# apollo510 register map
Vendor: Ambiq Micro; Series: Apollo; File version: 1.0
CPU: CM55 r1p1, little endian, MPU, FPU, double-precision FPU, DSP, I-cache, D-cache, VTOR, ITCM, DTCM, 4 interrupt priority bits, 0 interrupts, 8 SAU regions
Registers are 32-bit, read-write, reset 0x0 unless marked. A register's access mark holds for its fields unless they carry their own. Offsets are from the block's base; [hi:lo] are bit positions; {n}, {i} and the like mark numbered series; 'fields as' and 'values as' point back to an identical list.

## GPIO (part 4 of 7) — General Purpose IO
Base 0x40010000
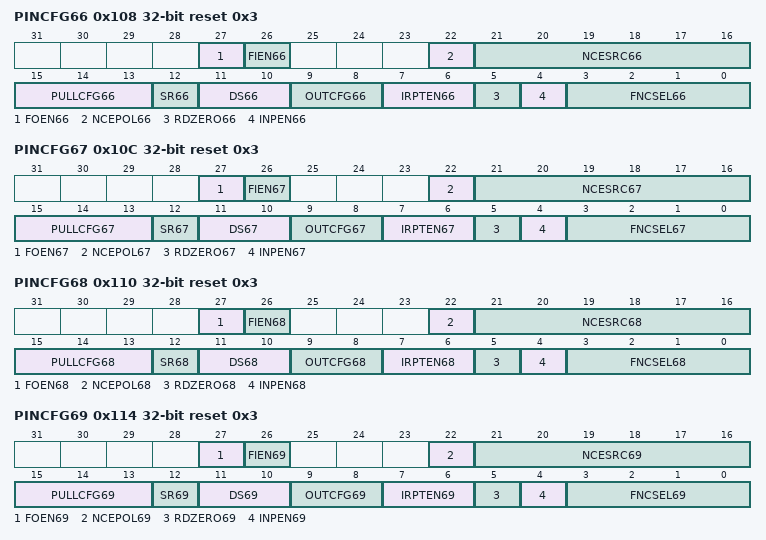
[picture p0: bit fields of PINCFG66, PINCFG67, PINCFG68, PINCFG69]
0x108 PINCFG66 reset 0x3 — Controls the operation of GPIO pin 66.
  [27] FOEN66 — Force output enable active regardless of function selected. Otherwise the selected function will enable the output only when needed
  [26] FIEN66 — Force input enable active regardless of function selected. Otherwise the selected function will enable the input only when needed
  [22] NCEPOL66 — Polarity select for NCE for GPIO 66
    0=LOW (Polarity is active low); 1=HIGH (Polarity is active high)
  [21:16] NCESRC66 — IOMSTR/MSPI N Chip Select 66, DISP control signals DE, CSX, and CS. Polarity is determined by CE_POLARITY field
    {v}=IOM0CE{v} (IOM 0 NCE {v} module) (v=0..3); {v}=IOM1CE{v-4} (IOM 1 NCE {v-4} module) (v=4..7); {v}=IOM2CE{v-8} (IOM 2 NCE {v-8} module) (v=8..11); {v}=IOM3CE{v-12} (IOM 3 NCE {v-12} module) (v=12..15); {v}=IOM4CE{v-16} (IOM 4 NCE {v-16} module) (v=16..19); {v}=IOM5CE{v-20} (IOM 5 NCE {v-20} module) (v=20..23); {v}=IOM6CE{v-24} (IOM 6 NCE {v-24} module) (v=24..27); {v}=IOM7CE{v-28} (IOM 7 NCE {v-28} module) (v=28..31); 48=DC_DPI_DE (DC DPI DE module); 49=DISP_CONT_CSX (DISP CONT CSX module); 50=DC_SPI_CS_N (DC SPI CS_N module); 51=DC_QSPI_CS_N (DC QSPI CS_N module); 52=DC_RESX (DC module RESX)
  [15:13] PULLCFG66 — Pullup/Pulldown configuration for GPIO 66
    0=DIS (No pullup or pulldown selected); 1=PD50K (50K Pulldown selected); 2=PU50K (50K Pullup selected)
  [12] SR66 — Configure high or low drive strength
    0=LDRV (Select the lower of the two drive strength selections); 1=HDRV (Select the higher of the two drive strength selections)
  [11:10] DS66 — Drive strength selection for High Speed GPIO 66
    0=0P12X_0P63X (0.12x output driver selected if SR66 = 0, 0.63x output driver selected if SR66 = 1); 1=0P25X_0P75X (0.25x output driver selected if SR66 = 0, 0.75x output driver selected if SR66 = 1); 2=0P37X_0P88X (0.37x output driver selected if SR66 = 0, 0.88x output driver selected if SR66 = 1); 3=0P5X_1P0X (0.5x output driver selected if SR66 = 0, 1.0x output driver selected if SR66 = 1)
  [9:8] OUTCFG66 — Pin IO mode selection for GPIO pin 66
    0=DIS (Output Disabled); 1=PUSHPULL (Output configured in push pull mode. Will drive 0 and 1 values on pin.); 2=OD (Output configured in open drain mode. Will only drive pin low, tristate otherwise.); 3=TS (Output configured in Tristate-able push pull mode. Will drive 0, 1 of HiZ on pin.)
  [7:6] IRPTEN66 — Interrupt enable for GPIO 66
    0=DIS (Interrupts are disabled for this GPIO); 1=INTFALL (Interrupts are enabled for falling edge transition on this GPIO); 2=INTRISE (Interrupts are enabled for rising edge transitions on this GPIO); 3=INTANY (Interrupts are enabled for any edge transition on this GPIO)
  [5] RDZERO66 — Return 0 for read data on GPIO 66
  [4] INPEN66 — Input enable for GPIO 66
  [3:0] FNCSEL66 — Function select for GPIO pin 66
    0=MSPI0_2 (MSPI Master 0 Interface Signal); 1=CLKOUT (Oscillator output clock); 2=SWO (Serial Wire Output); 3=GPIO (General purpose I/O); 4=UART0TX (UART transmit output (UART 0)); 5=UART1TX (UART transmit output (UART 1)); 6=CT66 (Timer/Counter input or output; Selection of direction is done via CTIMER register settings.); 7=NCE66 (IOMSTR N Chip Select. Polarity is determined by CE_POLARITY field); 8=OBSBUS2 (Observation bus bit 2); 11=FPIO (Fast PIO)
0x10C PINCFG67 reset 0x3 — Controls the operation of GPIO pin 67.
  [27] FOEN67 — Force output enable active regardless of function selected. Otherwise the selected function will enable the output only when needed
  [26] FIEN67 — Force input enable active regardless of function selected. Otherwise the selected function will enable the input only when needed
  [22] NCEPOL67 — Polarity select for NCE for GPIO 67
    values as PINCFG66.NCEPOL66
  [21:16] NCESRC67 — IOMSTR/MSPI N Chip Select 67, DISP control signals DE, CSX, and CS. Polarity is determined by CE_POLARITY field
    values as PINCFG66.NCESRC66
  [15:13] PULLCFG67 — Pullup/Pulldown configuration for GPIO 67
    values as PINCFG66.PULLCFG66
  [12] SR67 — Configure high or low drive strength
    values as PINCFG66.SR66
  [11:10] DS67 — Drive strength selection for High Speed GPIO 67
    0=0P12X_0P63X (0.12x output driver selected if SR67 = 0, 0.63x output driver selected if SR67 = 1); 1=0P25X_0P75X (0.25x output driver selected if SR67 = 0, 0.75x output driver selected if SR67 = 1); 2=0P37X_0P88X (0.37x output driver selected if SR67 = 0, 0.88x output driver selected if SR67 = 1); 3=0P5X_1P0X (0.5x output driver selected if SR67 = 0, 1.0x output driver selected if SR67 = 1)
  [9:8] OUTCFG67 — Pin IO mode selection for GPIO pin 67
    values as PINCFG66.OUTCFG66
  [7:6] IRPTEN67 — Interrupt enable for GPIO 67
    values as PINCFG66.IRPTEN66
  [5] RDZERO67 — Return 0 for read data on GPIO 67
  [4] INPEN67 — Input enable for GPIO 67
  [3:0] FNCSEL67 — Function select for GPIO pin 67
    0=MSPI0_3 (MSPI Master 0 Interface Signal); 1=CLKOUT (Oscillator output clock); 2=SWO (Serial Wire Output); 3=GPIO (General purpose I/O); 4=UART2TX (UART transmit output (UART 2)); 5=UART3TX (UART transmit output (UART 3)); 6=CT67 (Timer/Counter input or output; Selection of direction is done via CTIMER register settings.); 7=NCE67 (IOMSTR N Chip Select. Polarity is determined by CE_POLARITY field); 8=OBSBUS3 (Observation bus bit 3); 11=FPIO (Fast PIO)
0x110 PINCFG68 reset 0x3 — Controls the operation of GPIO pin 68.
  [27] FOEN68 — Force output enable active regardless of function selected. Otherwise the selected function will enable the output only when needed
  [26] FIEN68 — Force input enable active regardless of function selected. Otherwise the selected function will enable the input only when needed
  [22] NCEPOL68 — Polarity select for NCE for GPIO 68
    values as PINCFG66.NCEPOL66
  [21:16] NCESRC68 — IOMSTR/MSPI N Chip Select 68, DISP control signals DE, CSX, and CS. Polarity is determined by CE_POLARITY field
    values as PINCFG66.NCESRC66
  [15:13] PULLCFG68 — Pullup/Pulldown configuration for GPIO 68
    values as PINCFG66.PULLCFG66
  [12] SR68 — Configure high or low drive strength
    values as PINCFG66.SR66
  [11:10] DS68 — Drive strength selection for High Speed GPIO 68
    0=0P12X_0P63X (0.12x output driver selected if SR68 = 0, 0.63x output driver selected if SR68 = 1); 1=0P25X_0P75X (0.25x output driver selected if SR68 = 0, 0.75x output driver selected if SR68 = 1); 2=0P37X_0P88X (0.37x output driver selected if SR68 = 0, 0.88x output driver selected if SR68 = 1); 3=0P5X_1P0X (0.5x output driver selected if SR68 = 0, 1.0x output driver selected if SR68 = 1)
  [9:8] OUTCFG68 — Pin IO mode selection for GPIO pin 68
    values as PINCFG66.OUTCFG66
  [7:6] IRPTEN68 — Interrupt enable for GPIO 68
    values as PINCFG66.IRPTEN66
  [5] RDZERO68 — Return 0 for read data on GPIO 68
  [4] INPEN68 — Input enable for GPIO 68
  [3:0] FNCSEL68 — Function select for GPIO pin 68
    0=MSPI0_4 (MSPI Master 0 Interface Signal); 1=SWO (Serial Wire Output); 3=GPIO (General purpose I/O); 4=UART0RX (UART receive input (UART 0)); 5=UART1RX (UART receive input (UART 1)); 6=CT68 (Timer/Counter input or output; Selection of direction is done via CTIMER register settings.); 7=NCE68 (IOMSTR N Chip Select. Polarity is determined by CE_POLARITY field); 8=OBSBUS4 (Observation bus bit 4); 11=FPIO (Fast PIO)
0x114 PINCFG69 reset 0x3 — Controls the operation of GPIO pin 69.
  [27] FOEN69 — Force output enable active regardless of function selected. Otherwise the selected function will enable the output only when needed
  [26] FIEN69 — Force input enable active regardless of function selected. Otherwise the selected function will enable the input only when needed
  [22] NCEPOL69 — Polarity select for NCE for GPIO 69
    values as PINCFG66.NCEPOL66
  [21:16] NCESRC69 — IOMSTR/MSPI N Chip Select 69, DISP control signals DE, CSX, and CS. Polarity is determined by CE_POLARITY field
    values as PINCFG66.NCESRC66
  [15:13] PULLCFG69 — Pullup/Pulldown configuration for GPIO 69
    values as PINCFG66.PULLCFG66
  [12] SR69 — Configure high or low drive strength
    values as PINCFG66.SR66
  [11:10] DS69 — Drive strength selection for High Speed GPIO 69
    0=0P12X_0P63X (0.12x output driver selected if SR69 = 0, 0.63x output driver selected if SR69 = 1); 1=0P25X_0P75X (0.25x output driver selected if SR69 = 0, 0.75x output driver selected if SR69 = 1); 2=0P37X_0P88X (0.37x output driver selected if SR69 = 0, 0.88x output driver selected if SR69 = 1); 3=0P5X_1P0X (0.5x output driver selected if SR69 = 0, 1.0x output driver selected if SR69 = 1)
  [9:8] OUTCFG69 — Pin IO mode selection for GPIO pin 69
    values as PINCFG66.OUTCFG66
  [7:6] IRPTEN69 — Interrupt enable for GPIO 69
    values as PINCFG66.IRPTEN66
  [5] RDZERO69 — Return 0 for read data on GPIO 69
  [4] INPEN69 — Input enable for GPIO 69
  [3:0] FNCSEL69 — Function select for GPIO pin 69
    0=MSPI0_5 (MSPI Master 0 Interface Signal); 1=32KHzXT (32kHZ from analog); 2=SWO (Serial Wire Output); 3=GPIO (General purpose I/O); 4=UART2RX (UART receive input (UART 2)); 5=UART3RX (UART receive input (UART 3)); 6=CT69 (Timer/Counter input or output; Selection of direction is done via CTIMER register settings.); 7=NCE69 (IOMSTR N Chip Select. Polarity is determined by CE_POLARITY field); 8=OBSBUS5 (Observation bus bit 5); 11=FPIO (Fast PIO)
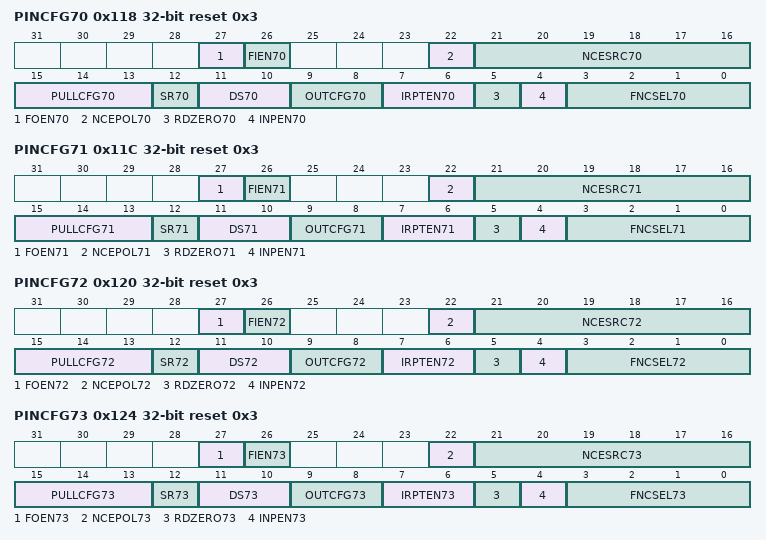
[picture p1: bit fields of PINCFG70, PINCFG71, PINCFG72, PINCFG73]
0x118 PINCFG70 reset 0x3 — Controls the operation of GPIO pin 70.
  [27] FOEN70 — Force output enable active regardless of function selected. Otherwise the selected function will enable the output only when needed
  [26] FIEN70 — Force input enable active regardless of function selected. Otherwise the selected function will enable the input only when needed
  [22] NCEPOL70 — Polarity select for NCE for GPIO 70
    values as PINCFG66.NCEPOL66
  [21:16] NCESRC70 — IOMSTR/MSPI N Chip Select 70, DISP control signals DE, CSX, and CS. Polarity is determined by CE_POLARITY field
    values as PINCFG66.NCESRC66
  [15:13] PULLCFG70 — Pullup/Pulldown configuration for GPIO 70
    values as PINCFG66.PULLCFG66
  [12] SR70 — Configure high or low drive strength
    values as PINCFG66.SR66
  [11:10] DS70 — Drive strength selection for High Speed GPIO 70
    0=0P12X_0P63X (0.12x output driver selected if SR70 = 0, 0.63x output driver selected if SR70 = 1); 1=0P25X_0P75X (0.25x output driver selected if SR70 = 0, 0.75x output driver selected if SR70 = 1); 2=0P37X_0P88X (0.37x output driver selected if SR70 = 0, 0.88x output driver selected if SR70 = 1); 3=0P5X_1P0X (0.5x output driver selected if SR70 = 0, 1.0x output driver selected if SR70 = 1)
  [9:8] OUTCFG70 — Pin IO mode selection for GPIO pin 70
    values as PINCFG66.OUTCFG66
  [7:6] IRPTEN70 — Interrupt enable for GPIO 70
    values as PINCFG66.IRPTEN66
  [5] RDZERO70 — Return 0 for read data on GPIO 70
  [4] INPEN70 — Input enable for GPIO 70
  [3:0] FNCSEL70 — Function select for GPIO pin 70
    0=MSPI0_6 (MSPI Master 0 Interface Signal); 1=32KHzXT (32kHZ from analog); 2=SWTRACE0 (Serial Wire Debug Trace Output 0); 3=GPIO (General purpose I/O); 4=UART0RTS (UART Request to Send (RTS) (UART 0)); 5=UART1RTS (UART Request to Send (RTS) (UART 1)); 6=CT70 (Timer/Counter input or output; Selection of direction is done via CTIMER register settings.); 7=NCE70 (IOMSTR N Chip Select. Polarity is determined by CE_POLARITY field); 8=OBSBUS6 (Observation bus bit 6); 11=FPIO (Fast PIO)
0x11C PINCFG71 reset 0x3 — Controls the operation of GPIO pin 71.
  [27] FOEN71 — Force output enable active regardless of function selected. Otherwise the selected function will enable the output only when needed
  [26] FIEN71 — Force input enable active regardless of function selected. Otherwise the selected function will enable the input only when needed
  [22] NCEPOL71 — Polarity select for NCE for GPIO 71
    values as PINCFG66.NCEPOL66
  [21:16] NCESRC71 — IOMSTR/MSPI N Chip Select 71, DISP control signals DE, CSX, and CS. Polarity is determined by CE_POLARITY field
    values as PINCFG66.NCESRC66
  [15:13] PULLCFG71 — Pullup/Pulldown configuration for GPIO 71
    values as PINCFG66.PULLCFG66
  [12] SR71 — Configure high or low drive strength
    values as PINCFG66.SR66
  [11:10] DS71 — Drive strength selection for High Speed GPIO 71
    0=0P12X_0P63X (0.12x output driver selected if SR71 = 0, 0.63x output driver selected if SR71 = 1); 1=0P25X_0P75X (0.25x output driver selected if SR71 = 0, 0.75x output driver selected if SR71 = 1); 2=0P37X_0P88X (0.37x output driver selected if SR71 = 0, 0.88x output driver selected if SR71 = 1); 3=0P5X_1P0X (0.5x output driver selected if SR71 = 0, 1.0x output driver selected if SR71 = 1)
  [9:8] OUTCFG71 — Pin IO mode selection for GPIO pin 71
    values as PINCFG66.OUTCFG66
  [7:6] IRPTEN71 — Interrupt enable for GPIO 71
    values as PINCFG66.IRPTEN66
  [5] RDZERO71 — Return 0 for read data on GPIO 71
  [4] INPEN71 — Input enable for GPIO 71
  [3:0] FNCSEL71 — Function select for GPIO pin 71
    0=MSPI0_7 (MSPI Master 0 Interface Signal); 1=CLKOUT (Oscillator output clock); 2=SWTRACE1 (Serial Wire Debug Trace Output 1); 3=GPIO (General purpose I/O); 4=UART0CTS (UART Clear to Send (CTS) (UART 0)); 5=UART3RTS (UART Request to Send (RTS) (UART 3)); 6=CT71 (Timer/Counter input or output; Selection of direction is done via CTIMER register settings.); 7=NCE71 (IOMSTR N Chip Select. Polarity is determined by CE_POLARITY field); 8=OBSBUS7 (Observation bus bit 7); 11=FPIO (Fast PIO)
0x120 PINCFG72 reset 0x3 — Controls the operation of GPIO pin 72.
  [27] FOEN72 — Force output enable active regardless of function selected. Otherwise the selected function will enable the output only when needed
  [26] FIEN72 — Force input enable active regardless of function selected. Otherwise the selected function will enable the input only when needed
  [22] NCEPOL72 — Polarity select for NCE for GPIO 72
    values as PINCFG66.NCEPOL66
  [21:16] NCESRC72 — IOMSTR/MSPI N Chip Select 72, DISP control signals DE, CSX, and CS. Polarity is determined by CE_POLARITY field
    values as PINCFG66.NCESRC66
  [15:13] PULLCFG72 — Pullup/Pulldown configuration for GPIO 72
    values as PINCFG66.PULLCFG66
  [12] SR72 — Configure high or low drive strength
    values as PINCFG66.SR66
  [11:10] DS72 — Drive strength selection for High Speed GPIO 72
    0=0P12X_0P63X (0.12x output driver selected if SR72 = 0, 0.63x output driver selected if SR72 = 1); 1=0P25X_0P75X (0.25x output driver selected if SR72 = 0, 0.75x output driver selected if SR72 = 1); 2=0P37X_0P88X (0.37x output driver selected if SR72 = 0, 0.88x output driver selected if SR72 = 1); 3=0P5X_1P0X (0.5x output driver selected if SR72 = 0, 1.0x output driver selected if SR72 = 1)
  [9:8] OUTCFG72 — Pin IO mode selection for GPIO pin 72
    values as PINCFG66.OUTCFG66
  [7:6] IRPTEN72 — Interrupt enable for GPIO 72
    values as PINCFG66.IRPTEN66
  [5] RDZERO72 — Return 0 for read data on GPIO 72
  [4] INPEN72 — Input enable for GPIO 72
  [3:0] FNCSEL72 — Function select for GPIO pin 72
    0=MSPI0_8 (MSPI Master 0 Interface Signal); 1=CLKOUT (Oscillator output clock); 2=SWTRACE2 (Serial Wire Debug Trace Output 2); 3=GPIO (General purpose I/O); 4=UART0TX (UART transmit output (UART 0)); 5=UART1TX (UART transmit output (UART 1)); 6=CT72 (Timer/Counter input or output; Selection of direction is done via CTIMER register settings.); 7=NCE72 (IOMSTR N Chip Select. Polarity is determined by CE_POLARITY field); 8=OBSBUS8 (Observation bus bit 8); 9=VCMPO (Output of the voltage comparator signal); 11=FPIO (Fast PIO)
0x124 PINCFG73 reset 0x3 — Controls the operation of GPIO pin 73.
  [27] FOEN73 — Force output enable active regardless of function selected. Otherwise the selected function will enable the output only when needed
  [26] FIEN73 — Force input enable active regardless of function selected. Otherwise the selected function will enable the input only when needed
  [22] NCEPOL73 — Polarity select for NCE for GPIO 73
    values as PINCFG66.NCEPOL66
  [21:16] NCESRC73 — IOMSTR/MSPI N Chip Select 73, DISP control signals DE, CSX, and CS. Polarity is determined by CE_POLARITY field
    values as PINCFG66.NCESRC66
  [15:13] PULLCFG73 — Pullup/Pulldown configuration for GPIO 73
    values as PINCFG66.PULLCFG66
  [12] SR73 — Configure high or low drive strength
    values as PINCFG66.SR66
  [11:10] DS73 — Drive strength selection for High Speed GPIO 73
    0=0P12X_0P63X (0.12x output driver selected if SR73 = 0, 0.63x output driver selected if SR73 = 1); 1=0P25X_0P75X (0.25x output driver selected if SR73 = 0, 0.75x output driver selected if SR73 = 1); 2=0P37X_0P88X (0.37x output driver selected if SR73 = 0, 0.88x output driver selected if SR73 = 1); 3=0P5X_1P0X (0.5x output driver selected if SR73 = 0, 1.0x output driver selected if SR73 = 1)
  [9:8] OUTCFG73 — Pin IO mode selection for GPIO pin 73
    values as PINCFG66.OUTCFG66
  [7:6] IRPTEN73 — Interrupt enable for GPIO 73
    values as PINCFG66.IRPTEN66
  [5] RDZERO73 — Return 0 for read data on GPIO 73
  [4] INPEN73 — Input enable for GPIO 73
  [3:0] FNCSEL73 — Function select for GPIO pin 73
    0=MSPI0_9 (MSPI Master 0 Interface Signal); 2=SWTRACE3 (Serial Wire Debug Trace Output 3); 3=GPIO (General purpose I/O); 4=UART2TX (UART transmit output (UART 2)); 5=UART3TX (UART transmit output (UART 3)); 6=CT73 (Timer/Counter input or output; Selection of direction is done via CTIMER register settings.); 7=NCE73 (IOMSTR N Chip Select. Polarity is determined by CE_POLARITY field); 8=OBSBUS9 (Observation bus bit 9); 11=FPIO (Fast PIO)
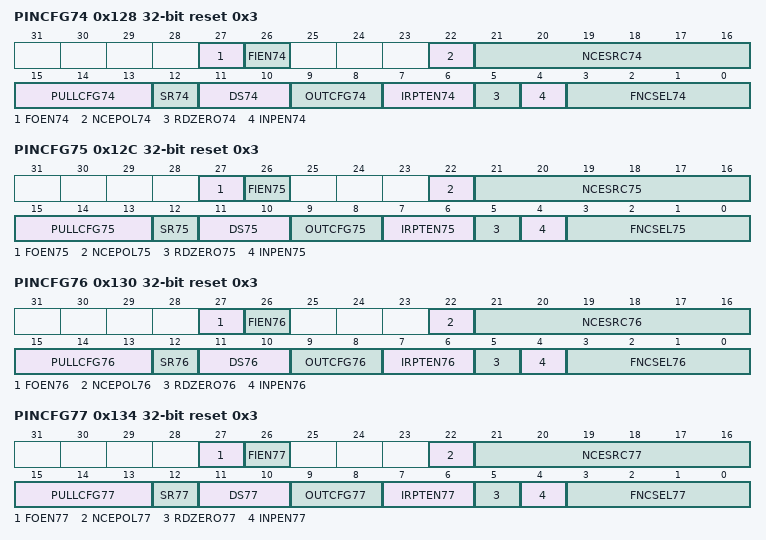
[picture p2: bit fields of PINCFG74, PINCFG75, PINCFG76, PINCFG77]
0x128 PINCFG74 reset 0x3 — Controls the operation of GPIO pin 74.
  [27] FOEN74 — Force output enable active regardless of function selected. Otherwise the selected function will enable the output only when needed
  [26] FIEN74 — Force input enable active regardless of function selected. Otherwise the selected function will enable the input only when needed
  [22] NCEPOL74 — Polarity select for NCE for GPIO 74
    values as PINCFG66.NCEPOL66
  [21:16] NCESRC74 — IOMSTR/MSPI N Chip Select 74, DISP control signals DE, CSX, and CS. Polarity is determined by CE_POLARITY field
    values as PINCFG66.NCESRC66
  [15:13] PULLCFG74 — Pullup/Pulldown configuration for GPIO 74
    0=DIS (No pullup or pulldown selected); 1=PD50K (50K Pulldown selected); 2=PU15K (1.5K Pullup selected); 3=PU6K (6K Pullup selected); 4=PU12K (12K Pullup selected); 5=PU24K (24K Pullup selected); 6=PU50K (50K Pullup selected); 7=PU100K (100K Pullup selected)
  [12] SR74 — Configure the slew rate
  [11:10] DS74 — Drive strength selection for GPIO 74
    0=0P1X (0.1x output driver selected); 1=0P5X (0.5x output driver selected); 2=0P75X (0.75x output driver selected); 3=1P0X (1.0x output driver selected)
  [9:8] OUTCFG74 — Pin IO mode selection for GPIO pin 74
    values as PINCFG66.OUTCFG66
  [7:6] IRPTEN74 — Interrupt enable for GPIO 74
    values as PINCFG66.IRPTEN66
  [5] RDZERO74 — Return 0 for read data on GPIO 74
  [4] INPEN74 — Input enable for GPIO 74
  [3:0] FNCSEL74 — Function select for GPIO pin 74
    0=MSPI2_0 (MSPI Master 2 Interface Signal); 3=GPIO (General purpose I/O); 4=UART0RX (UART receive input (UART 0)); 5=UART3CTS (UART Clear to Send (CTS) (UART 3)); 6=CT74 (Timer/Counter input or output; Selection of direction is done via CTIMER register settings.); 7=NCE74 (IOMSTR N Chip Select. Polarity is determined by CE_POLARITY field); 8=OBSBUS10 (Observation bus bit 10); 11=FPIO (Fast PIO)
0x12C PINCFG75 reset 0x3 — Controls the operation of GPIO pin 75.
  [27] FOEN75 — Force output enable active regardless of function selected. Otherwise the selected function will enable the output only when needed
  [26] FIEN75 — Force input enable active regardless of function selected. Otherwise the selected function will enable the input only when needed
  [22] NCEPOL75 — Polarity select for NCE for GPIO 75
    values as PINCFG66.NCEPOL66
  [21:16] NCESRC75 — IOMSTR/MSPI N Chip Select 75, DISP control signals DE, CSX, and CS. Polarity is determined by CE_POLARITY field
    values as PINCFG66.NCESRC66
  [15:13] PULLCFG75 — Pullup/Pulldown configuration for GPIO 75
    values as PINCFG74.PULLCFG74
  [12] SR75 — Configure the slew rate
  [11:10] DS75 — Drive strength selection for GPIO 75
    values as PINCFG74.DS74
  [9:8] OUTCFG75 — Pin IO mode selection for GPIO pin 75
    values as PINCFG66.OUTCFG66
  [7:6] IRPTEN75 — Interrupt enable for GPIO 75
    values as PINCFG66.IRPTEN66
  [5] RDZERO75 — Return 0 for read data on GPIO 75
  [4] INPEN75 — Input enable for GPIO 75
  [3:0] FNCSEL75 — Function select for GPIO pin 75
    0=MSPI2_1 (MSPI Master 2 Interface Signal); 1=32KHzXT (32kHZ from analog); 3=GPIO (General purpose I/O); 4=UART2RX (UART receive input (UART 2)); 5=UART3RX (UART receive input (UART 3)); 6=CT75 (Timer/Counter input or output; Selection of direction is done via CTIMER register settings.); 7=NCE75 (IOMSTR N Chip Select. Polarity is determined by CE_POLARITY field); 8=OBSBUS11 (Observation bus bit 11); 11=FPIO (Fast PIO)
0x130 PINCFG76 reset 0x3 — Controls the operation of GPIO pin 76.
  [27] FOEN76 — Force output enable active regardless of function selected. Otherwise the selected function will enable the output only when needed
  [26] FIEN76 — Force input enable active regardless of function selected. Otherwise the selected function will enable the input only when needed
  [22] NCEPOL76 — Polarity select for NCE for GPIO 76
    values as PINCFG66.NCEPOL66
  [21:16] NCESRC76 — IOMSTR/MSPI N Chip Select 76, DISP control signals DE, CSX, and CS. Polarity is determined by CE_POLARITY field
    values as PINCFG66.NCESRC66
  [15:13] PULLCFG76 — Pullup/Pulldown configuration for GPIO 76
    values as PINCFG74.PULLCFG74
  [12] SR76 — Configure the slew rate
  [11:10] DS76 — Drive strength selection for GPIO 76
    values as PINCFG74.DS74
  [9:8] OUTCFG76 — Pin IO mode selection for GPIO pin 76
    values as PINCFG66.OUTCFG66
  [7:6] IRPTEN76 — Interrupt enable for GPIO 76
    values as PINCFG66.IRPTEN66
  [5] RDZERO76 — Return 0 for read data on GPIO 76
  [4] INPEN76 — Input enable for GPIO 76
  [3:0] FNCSEL76 — Function select for GPIO pin 76
    0=MSPI2_2 (MSPI Master 2 Interface Signal); 1=32KHzXT (32kHZ from analog); 3=GPIO (General purpose I/O); 4=UART0RTS (UART Request to Send (RTS) (UART 0)); 5=UART1RTS (UART Request to Send (RTS) (UART 1)); 6=CT76 (Timer/Counter input or output; Selection of direction is done via CTIMER register settings.); 7=NCE76 (IOMSTR N Chip Select. Polarity is determined by CE_POLARITY field); 8=OBSBUS12 (Observation bus bit 12); 11=FPIO (Fast PIO)
0x134 PINCFG77 reset 0x3 — Controls the operation of GPIO pin 77.
  [27] FOEN77 — Force output enable active regardless of function selected. Otherwise the selected function will enable the output only when needed
  [26] FIEN77 — Force input enable active regardless of function selected. Otherwise the selected function will enable the input only when needed
  [22] NCEPOL77 — Polarity select for NCE for GPIO 77
    values as PINCFG66.NCEPOL66
  [21:16] NCESRC77 — IOMSTR/MSPI N Chip Select 77, DISP control signals DE, CSX, and CS. Polarity is determined by CE_POLARITY field
    values as PINCFG66.NCESRC66
  [15:13] PULLCFG77 — Pullup/Pulldown configuration for GPIO 77
    values as PINCFG74.PULLCFG74
  [12] SR77 — Configure the slew rate
  [11:10] DS77 — Drive strength selection for GPIO 77
    values as PINCFG74.DS74
  [9:8] OUTCFG77 — Pin IO mode selection for GPIO pin 77
    values as PINCFG66.OUTCFG66
  [7:6] IRPTEN77 — Interrupt enable for GPIO 77
    values as PINCFG66.IRPTEN66
  [5] RDZERO77 — Return 0 for read data on GPIO 77
  [4] INPEN77 — Input enable for GPIO 77
  [3:0] FNCSEL77 — Function select for GPIO pin 77
    0=MSPI2_3 (MSPI Master 2 Interface Signal); 3=GPIO (General purpose I/O); 4=UART0CTS (UART Clear to Send (CTS) (UART 0)); 5=UART1CTS (UART Clear to Send (CTS) (UART 1)); 6=CT77 (Timer/Counter input or output; Selection of direction is done via CTIMER register settings.); 7=NCE77 (IOMSTR N Chip Select. Polarity is determined by CE_POLARITY field); 8=OBSBUS13 (Observation bus bit 13); 11=FPIO (Fast PIO)
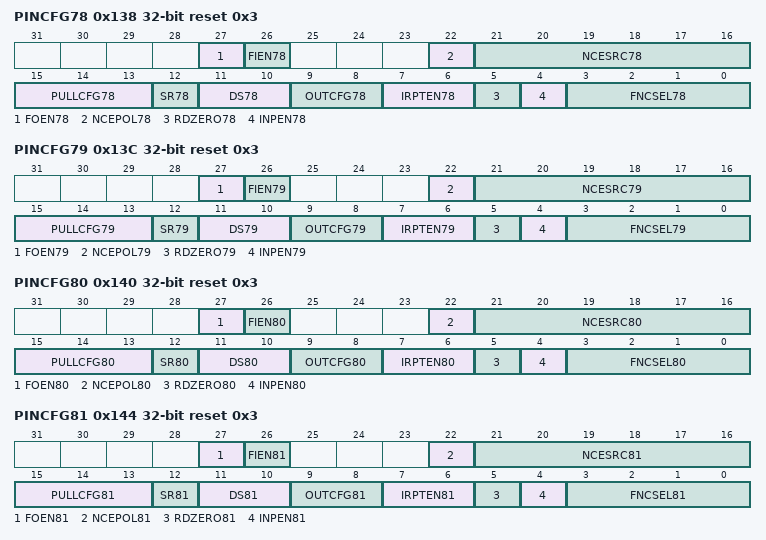
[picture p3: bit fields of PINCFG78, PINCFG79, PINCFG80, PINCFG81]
0x138 PINCFG78 reset 0x3 — Controls the operation of GPIO pin 78.
  [27] FOEN78 — Force output enable active regardless of function selected. Otherwise the selected function will enable the output only when needed
  [26] FIEN78 — Force input enable active regardless of function selected. Otherwise the selected function will enable the input only when needed
  [22] NCEPOL78 — Polarity select for NCE for GPIO 78
    values as PINCFG66.NCEPOL66
  [21:16] NCESRC78 — IOMSTR/MSPI N Chip Select 78, DISP control signals DE, CSX, and CS. Polarity is determined by CE_POLARITY field
    values as PINCFG66.NCESRC66
  [15:13] PULLCFG78 — Pullup/Pulldown configuration for GPIO 78
    values as PINCFG74.PULLCFG74
  [12] SR78 — Configure the slew rate
  [11:10] DS78 — Drive strength selection for GPIO 78
    values as PINCFG74.DS74
  [9:8] OUTCFG78 — Pin IO mode selection for GPIO pin 78
    values as PINCFG66.OUTCFG66
  [7:6] IRPTEN78 — Interrupt enable for GPIO 78
    values as PINCFG66.IRPTEN66
  [5] RDZERO78 — Return 0 for read data on GPIO 78
  [4] INPEN78 — Input enable for GPIO 78
  [3:0] FNCSEL78 — Function select for GPIO pin 78
    0=MSPI2_4 (MSPI Master 2 Interface Signal); 3=GPIO (General purpose I/O); 4=UART0TX (UART transmit output (UART 0)); 5=UART1TX (UART transmit output (UART 1)); 6=CT78 (Timer/Counter input or output; Selection of direction is done via CTIMER register settings.); 7=NCE78 (IOMSTR N Chip Select. Polarity is determined by CE_POLARITY field); 8=OBSBUS14 (Observation bus bit 14); 11=FPIO (Fast PIO)
0x13C PINCFG79 reset 0x3 — Controls the operation of GPIO pin 79.
  [27] FOEN79 — Force output enable active regardless of function selected. Otherwise the selected function will enable the output only when needed
  [26] FIEN79 — Force input enable active regardless of function selected. Otherwise the selected function will enable the input only when needed
  [22] NCEPOL79 — Polarity select for NCE for GPIO 79
    values as PINCFG66.NCEPOL66
  [21:16] NCESRC79 — IOMSTR/MSPI N Chip Select 79, DISP control signals DE, CSX, and CS. Polarity is determined by CE_POLARITY field
    values as PINCFG66.NCESRC66
  [15:13] PULLCFG79 — Pullup/Pulldown configuration for GPIO 79
    values as PINCFG74.PULLCFG74
  [12] SR79 — Configure the slew rate
  [11:10] DS79 — Drive strength selection for GPIO 79
    values as PINCFG74.DS74
  [9:8] OUTCFG79 — Pin IO mode selection for GPIO pin 79
    values as PINCFG66.OUTCFG66
  [7:6] IRPTEN79 — Interrupt enable for GPIO 79
    values as PINCFG66.IRPTEN66
  [5] RDZERO79 — Return 0 for read data on GPIO 79
  [4] INPEN79 — Input enable for GPIO 79
  [3:0] FNCSEL79 — Function select for GPIO pin 79
    0=MSPI2_5 (MSPI Master 2 Interface Signal); 1=DISP_QSPI_D0_OUT (Display SPI Data0 Out); 2=DISP_QSPI_D0 (Display SPI Data0); 3=GPIO (General purpose I/O); 4=SWO (Serial Wire Output); 5=UART1RTS (UART Request to Send (RTS) (UART 1)); 6=CT79 (Timer/Counter input or output; Selection of direction is done via CTIMER register settings.); 7=NCE79 (IOMSTR N Chip Select. Polarity is determined by CE_POLARITY field); 8=OBSBUS15 (Observation bus bit 15); 9=DISP_SPI_SD (Display SPI Data); 10=DISP_SPI_SDO (Display SPI Data Out); 11=FPIO (Fast PIO)
0x140 PINCFG80 reset 0x3 — Controls the operation of GPIO pin 80.
  [27] FOEN80 — Force output enable active regardless of function selected. Otherwise the selected function will enable the output only when needed
  [26] FIEN80 — Force input enable active regardless of function selected. Otherwise the selected function will enable the input only when needed
  [22] NCEPOL80 — Polarity select for NCE for GPIO 80
    values as PINCFG66.NCEPOL66
  [21:16] NCESRC80 — IOMSTR/MSPI N Chip Select 80, DISP control signals DE, CSX, and CS. Polarity is determined by CE_POLARITY field
    values as PINCFG66.NCESRC66
  [15:13] PULLCFG80 — Pullup/Pulldown configuration for GPIO 80
    values as PINCFG74.PULLCFG74
  [12] SR80 — Configure the slew rate
  [11:10] DS80 — Drive strength selection for GPIO 80
    values as PINCFG74.DS74
  [9:8] OUTCFG80 — Pin IO mode selection for GPIO pin 80
    values as PINCFG66.OUTCFG66
  [7:6] IRPTEN80 — Interrupt enable for GPIO 80
    values as PINCFG66.IRPTEN66
  [5] RDZERO80 — Return 0 for read data on GPIO 80
  [4] INPEN80 — Input enable for GPIO 80
  [3:0] FNCSEL80 — Function select for GPIO pin 80
    0=MSPI2_6 (MSPI Master 2 Interface Signal); 1=CLKOUT (Oscillator output clock); 2=DISP_QSPI_D1 (Display SPI Data1); 3=GPIO (General purpose I/O); 4=SWTRACE0 (Serial Wire Debug Trace Output 0); 5=UART2CTS (UART Clear to Send (CTS) (UART 2)); 6=CT80 (Timer/Counter input or output; Selection of direction is done via CTIMER register settings.); 7=NCE80 (IOMSTR N Chip Select. Polarity is determined by CE_POLARITY field); 8=OBSBUS0 (Observation bus bit 0); 9=DISP_SPI_DCX (Display SPI DCx); 11=FPIO (Fast PIO)
0x144 PINCFG81 reset 0x3 — Controls the operation of GPIO pin 81.
  [27] FOEN81 — Force output enable active regardless of function selected. Otherwise the selected function will enable the output only when needed
  [26] FIEN81 — Force input enable active regardless of function selected. Otherwise the selected function will enable the input only when needed
  [22] NCEPOL81 — Polarity select for NCE for GPIO 81
    values as PINCFG66.NCEPOL66
  [21:16] NCESRC81 — IOMSTR/MSPI N Chip Select 81, DISP control signals DE, CSX, and CS. Polarity is determined by CE_POLARITY field
    values as PINCFG66.NCESRC66
  [15:13] PULLCFG81 — Pullup/Pulldown configuration for GPIO 81
    values as PINCFG74.PULLCFG74
  [12] SR81 — Configure the slew rate
  [11:10] DS81 — Drive strength selection for GPIO 81
    values as PINCFG74.DS74
  [9:8] OUTCFG81 — Pin IO mode selection for GPIO pin 81
    values as PINCFG66.OUTCFG66
  [7:6] IRPTEN81 — Interrupt enable for GPIO 81
    values as PINCFG66.IRPTEN66
  [5] RDZERO81 — Return 0 for read data on GPIO 81
  [4] INPEN81 — Input enable for GPIO 81
  [3:0] FNCSEL81 — Function select for GPIO pin 81
    0=MSPI2_7 (MSPI Master 2 Interface Signal); 1=CLKOUT (Oscillator output clock); 2=DISP_QSPI_SCK (Display SPI CLK); 3=GPIO (General purpose I/O); 4=SWTRACE1 (Serial Wire Debug Trace Output 1); 5=UART2RTS (UART Request to Send (RTS) (UART 2)); 6=CT81 (Timer/Counter input or output; Selection of direction is done via CTIMER register settings.); 7=NCE81 (IOMSTR N Chip Select. Polarity is determined by CE_POLARITY field); 8=OBSBUS1 (Observation bus bit 1); 9=DISP_SPI_SCK (Display SPI Clock); 11=FPIO (Fast PIO)
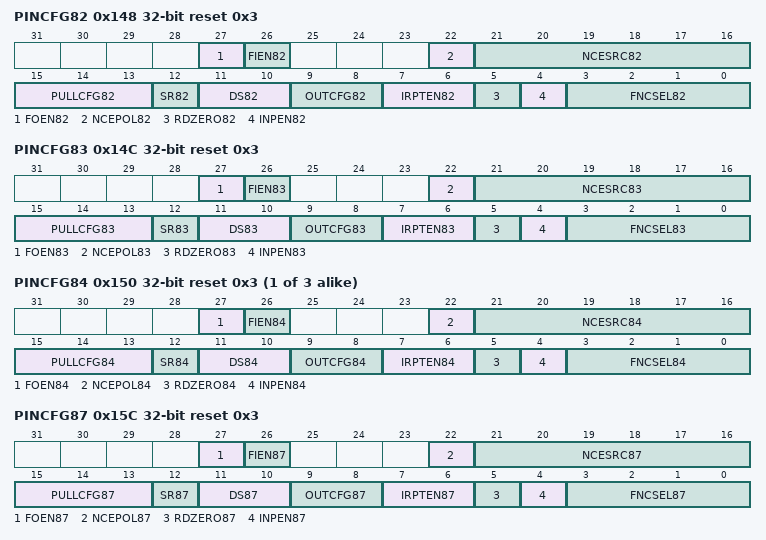
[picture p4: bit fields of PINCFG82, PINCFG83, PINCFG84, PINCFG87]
0x148 PINCFG82 reset 0x3 — Controls the operation of GPIO pin 82.
  [27] FOEN82 — Force output enable active regardless of function selected. Otherwise the selected function will enable the output only when needed
  [26] FIEN82 — Force input enable active regardless of function selected. Otherwise the selected function will enable the input only when needed
  [22] NCEPOL82 — Polarity select for NCE for GPIO 82
    values as PINCFG66.NCEPOL66
  [21:16] NCESRC82 — IOMSTR/MSPI N Chip Select 82, DISP control signals DE, CSX, and CS. Polarity is determined by CE_POLARITY field
    values as PINCFG66.NCESRC66
  [15:13] PULLCFG82 — Pullup/Pulldown configuration for GPIO 82
    values as PINCFG74.PULLCFG74
  [12] SR82 — Configure the slew rate
  [11:10] DS82 — Drive strength selection for GPIO 82
    values as PINCFG74.DS74
  [9:8] OUTCFG82 — Pin IO mode selection for GPIO pin 82
    values as PINCFG66.OUTCFG66
  [7:6] IRPTEN82 — Interrupt enable for GPIO 82
    values as PINCFG66.IRPTEN66
  [5] RDZERO82 — Return 0 for read data on GPIO 82
  [4] INPEN82 — Input enable for GPIO 82
  [3:0] FNCSEL82 — Function select for GPIO pin 82
    0=MSPI2_8 (MSPI Master 2 Interface Signal); 1=32KHzXT (32kHZ from analog); 2=DISP_QSPI_D2 (Display SPI Data2); 3=GPIO (General purpose I/O); 4=SWTRACE2 (Serial Wire Debug Trace Output 2); 5=UART3CTS (UART Clear to Send (CTS) (UART 3)); 6=CT82 (Timer/Counter input or output; Selection of direction is done via CTIMER register settings.); 7=NCE82 (IOMSTR N Chip Select. Polarity is determined by CE_POLARITY field); 8=OBSBUS2 (Observation bus bit 2); 9=DISP_SPI_SDI (Display SPI Data In); 11=FPIO (Fast PIO)
0x14C PINCFG83 reset 0x3 — Controls the operation of GPIO pin 83.
  [27] FOEN83 — Force output enable active regardless of function selected. Otherwise the selected function will enable the output only when needed
  [26] FIEN83 — Force input enable active regardless of function selected. Otherwise the selected function will enable the input only when needed
  [22] NCEPOL83 — Polarity select for NCE for GPIO 83
    values as PINCFG66.NCEPOL66
  [21:16] NCESRC83 — IOMSTR/MSPI N Chip Select 83, DISP control signals DE, CSX, and CS. Polarity is determined by CE_POLARITY field
    values as PINCFG66.NCESRC66
  [15:13] PULLCFG83 — Pullup/Pulldown configuration for GPIO 83
    values as PINCFG74.PULLCFG74
  [12] SR83 — Configure the slew rate
  [11:10] DS83 — Drive strength selection for GPIO 83
    values as PINCFG74.DS74
  [9:8] OUTCFG83 — Pin IO mode selection for GPIO pin 83
    values as PINCFG66.OUTCFG66
  [7:6] IRPTEN83 — Interrupt enable for GPIO 83
    values as PINCFG66.IRPTEN66
  [5] RDZERO83 — Return 0 for read data on GPIO 83
  [4] INPEN83 — Input enable for GPIO 83
  [3:0] FNCSEL83 — Function select for GPIO pin 83
    0=MSPI2_9 (MSPI Master 2 Interface Signal); 1=32KHzXT (32kHZ from analog); 2=DISP_QSPI_D3 (Display SPI Data3); 3=GPIO (General purpose I/O); 4=SWTRACE3 (Serial Wire Debug Trace Output 3); 5=UART3RTS (UART Request to Send (RTS) (UART 3)); 6=CT83 (Timer/Counter input or output; Selection of direction is done via CTIMER register settings.); 7=NCE83 (IOMSTR N Chip Select. Polarity is determined by CE_POLARITY field); 8=OBSBUS3 (Observation bus bit 3); 9=DISP_SPI_RST (Display SPI RST); 10=SLMISO (SPI Slave output data); 11=FPIO (Fast PIO)
{0x0+4i} PINCFG{i} reset 0x3 (i=84..86) — Controls the operation of GPIO pin {i}.
  [27] FOEN{i} — Force output enable active regardless of function selected. Otherwise the selected function will enable the output only when needed
  [26] FIEN{i} — Force input enable active regardless of function selected. Otherwise the selected function will enable the input only when needed
  [22] NCEPOL{i} — Polarity select for NCE for GPIO {i}
    values as PINCFG66.NCEPOL66
  [21:16] NCESRC{i} — IOMSTR/MSPI N Chip Select {i}, DISP control signals DE, CSX, and CS. Polarity is determined by CE_POLARITY field
    values as PINCFG66.NCESRC66
  [15:13] PULLCFG{i} — Pullup/Pulldown configuration for GPIO {i}
    values as PINCFG74.PULLCFG74
  [12] SR{i} — Configure the slew rate
  [11:10] DS{i} — Drive strength selection for GPIO {i}
    values as PINCFG74.DS74
  [9:8] OUTCFG{i} — Pin IO mode selection for GPIO pin {i}
    values as PINCFG66.OUTCFG66
  [7:6] IRPTEN{i} — Interrupt enable for GPIO {i}
    values as PINCFG66.IRPTEN66
  [5] RDZERO{i} — Return 0 for read data on GPIO {i}
  [4] INPEN{i} — Input enable for GPIO {i}
  [3:0] FNCSEL{i} — Function select for GPIO pin {i}
    2=SDIF0_DAT{i-84} (SD/SDIO/MMC0 Data{i-84} pin); 3=GPIO (General purpose I/O); 6=CT{i} (Timer/Counter input or output; Selection of direction is done via CTIMER register settings.); 7=NCE{i} (IOMSTR N Chip Select. Polarity is determined by CE_POLARITY field); 8=OBSBUS{i-80} (Observation bus bit {i-80}); 11=FPIO (Fast PIO)
0x15C PINCFG87 reset 0x3 — Controls the operation of GPIO pin 87.
  [27] FOEN87 — Force output enable active regardless of function selected. Otherwise the selected function will enable the output only when needed
  [26] FIEN87 — Force input enable active regardless of function selected. Otherwise the selected function will enable the input only when needed
  [22] NCEPOL87 — Polarity select for NCE for GPIO 87
    values as PINCFG66.NCEPOL66
  [21:16] NCESRC87 — IOMSTR/MSPI N Chip Select 87, DISP control signals DE, CSX, and CS. Polarity is determined by CE_POLARITY field
    values as PINCFG66.NCESRC66
  [15:13] PULLCFG87 — Pullup/Pulldown configuration for GPIO 87
    values as PINCFG74.PULLCFG74
  [12] SR87 — Configure the slew rate
  [11:10] DS87 — Drive strength selection for GPIO 87
    values as PINCFG74.DS74
  [9:8] OUTCFG87 — Pin IO mode selection for GPIO pin 87
    values as PINCFG66.OUTCFG66
  [7:6] IRPTEN87 — Interrupt enable for GPIO 87
    values as PINCFG66.IRPTEN66
  [5] RDZERO87 — Return 0 for read data on GPIO 87
  [4] INPEN87 — Input enable for GPIO 87
  [3:0] FNCSEL87 — Function select for GPIO pin 87
    2=SDIF0_DAT3 (SD/SDIO/MMC0 Data3 pin); 3=GPIO (General purpose I/O); 6=CT87 (Timer/Counter input or output; Selection of direction is done via CTIMER register settings.); 7=NCE87 (IOMSTR N Chip Select. Polarity is determined by CE_POLARITY field); 8=OBSBUS7 (Observation bus bit 7); 9=DISP_TE (Display TE input); 11=FPIO (Fast PIO)
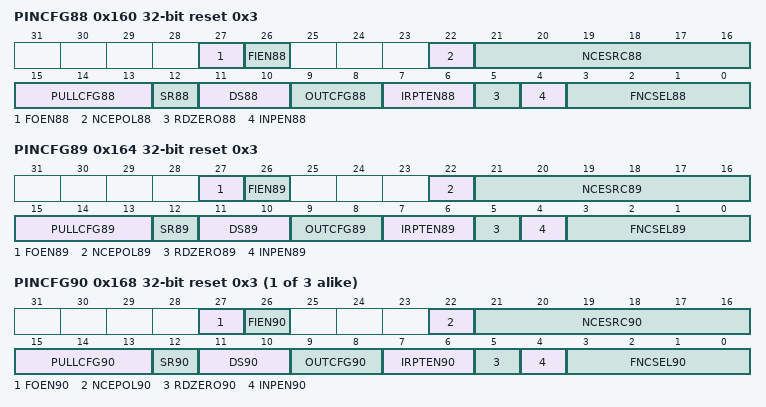
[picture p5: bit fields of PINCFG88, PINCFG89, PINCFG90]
0x160 PINCFG88 reset 0x3 — Controls the operation of GPIO pin 88.
  [27] FOEN88 — Force output enable active regardless of function selected. Otherwise the selected function will enable the output only when needed
  [26] FIEN88 — Force input enable active regardless of function selected. Otherwise the selected function will enable the input only when needed
  [22] NCEPOL88 — Polarity select for NCE for GPIO 88
    values as PINCFG66.NCEPOL66
  [21:16] NCESRC88 — IOMSTR/MSPI N Chip Select 88, DISP control signals DE, CSX, and CS. Polarity is determined by CE_POLARITY field
    values as PINCFG66.NCESRC66
  [15:13] PULLCFG88 — Pullup/Pulldown configuration for GPIO 88
    values as PINCFG74.PULLCFG74
  [12] SR88 — Configure the slew rate
  [11:10] DS88 — Drive strength selection for GPIO 88
    values as PINCFG74.DS74
  [9:8] OUTCFG88 — Pin IO mode selection for GPIO pin 88
    values as PINCFG66.OUTCFG66
  [7:6] IRPTEN88 — Interrupt enable for GPIO 88
    values as PINCFG66.IRPTEN66
  [5] RDZERO88 — Return 0 for read data on GPIO 88
  [4] INPEN88 — Input enable for GPIO 88
  [3:0] FNCSEL88 — Function select for GPIO pin 88
    2=SDIF0_CLKOUT (SD/SDIO/MMC0 Clock to Card (CLK)); 3=GPIO (General purpose I/O); 6=CT88 (Timer/Counter input or output; Selection of direction is done via CTIMER register settings.); 7=NCE88 (IOMSTR N Chip Select. Polarity is determined by CE_POLARITY field); 8=OBSBUS8 (Observation bus bit 8); 11=FPIO (Fast PIO)
0x164 PINCFG89 reset 0x3 — Controls the operation of GPIO pin 89.
  [27] FOEN89 — Force output enable active regardless of function selected. Otherwise the selected function will enable the output only when needed
  [26] FIEN89 — Force input enable active regardless of function selected. Otherwise the selected function will enable the input only when needed
  [22] NCEPOL89 — Polarity select for NCE for GPIO 89
    values as PINCFG66.NCEPOL66
  [21:16] NCESRC89 — IOMSTR/MSPI N Chip Select 89, DISP control signals DE, CSX, and CS. Polarity is determined by CE_POLARITY field
    values as PINCFG66.NCESRC66
  [15:13] PULLCFG89 — Pullup/Pulldown configuration for GPIO 89
    values as PINCFG74.PULLCFG74
  [12] SR89 — Configure the slew rate
  [11:10] DS89 — Drive strength selection for GPIO 89
    0=0P1X (0.1x output driver selected); 1=0P5X (0.5x output driver selected)
  [9:8] OUTCFG89 — Pin IO mode selection for GPIO pin 89
    values as PINCFG66.OUTCFG66
  [7:6] IRPTEN89 — Interrupt enable for GPIO 89
    values as PINCFG66.IRPTEN66
  [5] RDZERO89 — Return 0 for read data on GPIO 89
  [4] INPEN89 — Input enable for GPIO 89
  [3:0] FNCSEL89 — Function select for GPIO pin 89
    3=GPIO (General purpose I/O); 6=CT89 (Timer/Counter input or output; Selection of direction is done via CTIMER register settings.); 7=NCE89 (IOMSTR N Chip Select. Polarity is determined by CE_POLARITY field); 8=OBSBUS9 (Observation bus bit 9); 9=DISP_SPI_RST (Display SPI RST); 11=FPIO (Fast PIO)
{0x0+4i} PINCFG{i} reset 0x3 (i=90..92) — Controls the operation of GPIO pin {i}.
  [27] FOEN{i} — Force output enable active regardless of function selected. Otherwise the selected function will enable the output only when needed
  [26] FIEN{i} — Force input enable active regardless of function selected. Otherwise the selected function will enable the input only when needed
  [22] NCEPOL{i} — Polarity select for NCE for GPIO {i}
    values as PINCFG66.NCEPOL66
  [21:16] NCESRC{i} — IOMSTR/MSPI N Chip Select {i}, DISP control signals DE, CSX, and CS. Polarity is determined by CE_POLARITY field
    values as PINCFG66.NCESRC66
  [15:13] PULLCFG{i} — Pullup/Pulldown configuration for GPIO {i}
    values as PINCFG74.PULLCFG74
  [12] SR{i} — Configure the slew rate
  [11:10] DS{i} — Drive strength selection for GPIO {i}
    values as PINCFG89.DS89
  [9:8] OUTCFG{i} — Pin IO mode selection for GPIO pin {i}
    values as PINCFG66.OUTCFG66
  [7:6] IRPTEN{i} — Interrupt enable for GPIO {i}
    values as PINCFG66.IRPTEN66
  [5] RDZERO{i} — Return 0 for read data on GPIO {i}
  [4] INPEN{i} — Input enable for GPIO {i}
  [3:0] FNCSEL{i} — Function select for GPIO pin {i}
    3=GPIO (General purpose I/O); 6=CT{i} (Timer/Counter input or output; Selection of direction is done via CTIMER register settings.); 7=NCE{i} (IOMSTR N Chip Select. Polarity is determined by CE_POLARITY field); 8=OBSBUS{i-80} (Observation bus bit {i-80}); 9=VCMPO (Output of the voltage comparator signal); 11=FPIO (Fast PIO)
